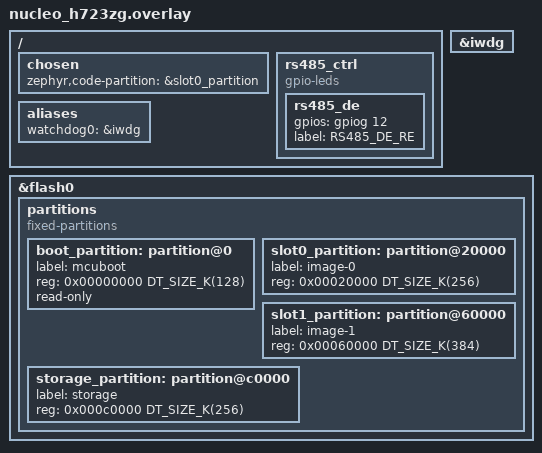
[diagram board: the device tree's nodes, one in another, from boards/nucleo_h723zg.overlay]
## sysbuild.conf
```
# Build MCUboot alongside the app (west build --sysbuild, implied by the
# presence of this file). Mode defaults to "swap using offset": MCUboot boots
# the new image on trial and automatically reverts to the previous one if it's
# never confirmed (see boot_write_img_confirmed() in src/main.c). No scratch
# partition is needed for this mode, matching the board's existing flash
# layout (same as fan_control_v2).
SB_CONFIG_BOOTLOADER_MCUBOOT=y
```

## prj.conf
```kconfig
# RS485 UART + DE GPIO
CONFIG_SERIAL=y
CONFIG_GPIO=y
CONFIG_UART_INTERRUPT_DRIVEN=y

# Hardware watchdog (IWDG): production safety net for the update flow. See
# APP_WDT_TIMEOUT_MS/APP_SELF_CONFIRM_GRACE_PERIOD_S in ./Kconfig.
# IWDG_STM32 auto-enables (default y, depends on the board's already-enabled
# &iwdg devicetree node).
CONFIG_WATCHDOG=y

# Settings-backed node address provisioning (rs485_envelope.c). Falls back to
# the board's existing storage_partition automatically - no devicetree change
# needed (settings_zms.c uses PARTITION_ID(storage_partition) when no
# zephyr,settings-partition chosen node exists).
#
# ZMS, not NVS: this board's erase-block-size is 128KB, but settings_nvs.c
# stores its sector size in a uint16_t (capped at 65535) and hard-errors
# with -EDOM ("Configuration error") the moment a hardware sector exceeds
# that - which every image on this board did, regardless of partition
# sizing. settings_zms.c's ZMS backend uses uint32_t instead and has no
# such ceiling; it's the intended replacement for exactly this case.
CONFIG_SETTINGS=y
CONFIG_ZMS=y
CONFIG_SETTINGS_ZMS=y

# Debug console on USART3 (ST-LINK VCP on this board, zephyr,console in the
# base devicetree) - a separate UART from LPUART1/RS485, safe to use for
# printk without disturbing the update transport.
CONFIG_CONSOLE=y
CONFIG_UART_CONSOLE=y
CONFIG_PRINTK=y
CONFIG_STDOUT_CONSOLE=y

# MCUboot image-manager, app side (same as fan_control_v2/prj.conf). IMG_MANAGER
# is needed for boot_write_img_confirmed(), and itself depends on FLASH_MAP +
# STREAM_FLASH (not auto-selected).
CONFIG_FLASH=y
CONFIG_FLASH_MAP=y
CONFIG_STREAM_FLASH=y
CONFIG_IMG_MANAGER=y
CONFIG_MCUBOOT_IMG_MANAGER=y

# mcumgr core + SMP-over-serial framing helpers. We deliberately do NOT enable
# CONFIG_MCUMGR_TRANSPORT_UART (it ties to a fixed zephyr,uart-mcumgr chosen
# console UART whose TX path can't be wrapped with RS485 DE control without
# patching a vendored Zephyr driver). Instead we drive the same shared
# encode/decode helpers (mcumgr_serial_tx_pkt/mcumgr_serial_process_frag) from
# our own transport in smp_rs485_transport.c.
CONFIG_NET_BUF=y
CONFIG_ZCBOR=y
CONFIG_BASE64=y
CONFIG_CRC=y
CONFIG_MCUMGR=y
# Selects CONFIG_MCUMGR_TRANSPORT_SERIAL_HAS_SMP_OVER_CONSOLE (see ./Kconfig) -
# that symbol has no prompt so it can't be set directly in a .conf fragment.
CONFIG_APP_RS485_SMP_TRANSPORT=y

# mcumgr command groups
CONFIG_MCUMGR_GRP_IMG=y
CONFIG_MCUMGR_GRP_OS=y

# Bumped so this build is a distinguishable, newer image for the mcumgr
# upload/test/confirm flow (adds the led1 1Hz blink) - not required for the
# swap itself (MCUBOOT_DOWNGRADE_PREVENTION isn't enabled), just for clarity.
CONFIG_MCUBOOT_IMGTOOL_SIGN_VERSION="0.0.1+0"

# Sizing
CONFIG_MCUMGR_TRANSPORT_NETBUF_SIZE=384
CONFIG_MCUMGR_TRANSPORT_NETBUF_COUNT=4
CONFIG_MAIN_STACK_SIZE=2048
CONFIG_SYSTEM_WORKQUEUE_STACK_SIZE=2304
```

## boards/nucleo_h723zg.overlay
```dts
/*
 * RS485 transceiver DE/RE control on PG12 (Arduino D7). RS485 data itself
 * rides LPUART1 (PB6/PB7 = Arduino D1/D0), already enabled by the board's
 * default devicetree - no pinctrl change needed here.
 */
/ {
	chosen {
		zephyr,code-partition = &slot0_partition;
	};

	rs485_ctrl: rs485_ctrl {
		compatible = "gpio-leds";

		rs485_de: rs485_de {
			gpios = <&gpiog 12 GPIO_ACTIVE_HIGH>;
			label = "RS485_DE_RE";
		};
	};

	aliases {
		watchdog0 = &iwdg;
	};
};

&iwdg {
	status = "okay";
};

/*
 * The upstream board devicetree doesn't define a flash partition table.
 * 1MB flash, 128KB erase sectors (stm32h723.dtsi) - every boundary below
 * lands on a sector boundary. No scratch partition: MCUboot's default
 * "swap using offset" mode doesn't need one (same as nucleo_g474re).
 *
 * storage gets 2 sectors (256K), not 1: settings_nvs.c's NVS backend
 * refuses to mount on fewer than 2 sectors (nvs_mount() in
 * subsys/kvss/nvs/nvs.c hard-errors "Configuration error - sector count"
 * below that) - it needs at least one spare sector to garbage-collect into.
 * A single 128K sector silently broke rs485_envelope_init() at boot (main()
 * returned before ever reaching the LED loop).
 *
 * slot1 (image-1) has ONE MORE sector than slot0 (image-0), not the same
 * count - required by swap-using-offset's app_max_size() (swap_offset.c):
 * it reserves a trailer sector in slot0 but a trailer *and* a padding sector
 * in slot1, so equal-sized slots make available_sec_sz compute to exactly
 * 0, capping the max bootable image size at 0 regardless of image content.
 * That's what actually caused "Image in the primary slot is not valid!"
 * for every image tried, verified via CONFIG_MCUBOOT_UTIL_LOG_LEVEL_DBG's
 * "TLV beyond image size" trace - not a signing or header problem at all.
 */
&flash0 {
	partitions {
		compatible = "fixed-partitions";
		#address-cells = <1>;
		#size-cells = <1>;

		boot_partition: partition@0 {
			label = "mcuboot";
			reg = <0x00000000 DT_SIZE_K(128)>;
			read-only;
		};

		slot0_partition: partition@20000 {
			label = "image-0";
			reg = <0x00020000 DT_SIZE_K(256)>;
		};

		slot1_partition: partition@60000 {
			label = "image-1";
			reg = <0x00060000 DT_SIZE_K(384)>;
		};

		storage_partition: partition@c0000 {
			label = "storage";
			reg = <0x000c0000 DT_SIZE_K(256)>;
		};
	};
};
```

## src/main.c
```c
#include <errno.h>
#include <zephyr/kernel.h>
#include <zephyr/device.h>
#include <zephyr/devicetree.h>
#include <zephyr/dfu/mcuboot.h>
#include <zephyr/drivers/gpio.h>
#include <zephyr/drivers/watchdog.h>
#include <zephyr/sys/printk.h>

#include "smp_rs485_transport.h"

#define LED0_NODE DT_ALIAS(led0)
#define LED1_NODE DT_ALIAS(led1)
#define WDT_NODE  DT_ALIAS(watchdog0)

/* LED1_TOGGLE_MS is a half-period (toggle interval), not a full cycle, so
 * 500ms here gives a 1Hz on/off blink rate - visual proof a new image (this
 * one) is actually running after an mcumgr update, distinct from led0's
 * faster 200ms heartbeat that both versions share.
 */
#define LED1_TOGGLE_MS 500

static const struct gpio_dt_spec led0 = GPIO_DT_SPEC_GET(LED0_NODE, gpios);
static const struct gpio_dt_spec led1 = GPIO_DT_SPEC_GET(LED1_NODE, gpios);
static const struct device *const wdt_dev = DEVICE_DT_GET(WDT_NODE);
static int wdt_channel_id = -1;

/*
 * Safety-net fallback: if the Pi never explicitly sends `mcumgr image
 * confirm` (mgmt/mcumgr/grp/img_mgmt/src/zephyr_img_mgmt.c's
 * img_mgmt_write_confirmed() already calls boot_write_img_confirmed() for
 * that path - no device code needed for it), the device confirms itself
 * after this many seconds of continuous, healthy operation, so it doesn't
 * stay in a perpetually-revertible "test" state for its whole operational
 * life. boot_is_img_confirmed() makes this a no-op if the Pi already
 * confirmed first.
 */
static void self_confirm_work_handler(struct k_work *work)
{
	ARG_UNUSED(work);

	if (!boot_is_img_confirmed()) {
		int rc = boot_write_img_confirmed();

		printk("rs485_mcumgr: self-confirm %s\n", rc == 0 ? "ok" : "failed");
	}
}
K_WORK_DELAYABLE_DEFINE(self_confirm_work, self_confirm_work_handler);

/*
 * Arms the IWDG so a bad update that hangs/crashes gets reset rather than
 * bricking the board: since the new image is never confirmed in that case,
 * MCUboot reverts to the last-known-good image on the next boot.
 * WDT_OPT_PAUSE_HALTED_BY_DBG freezes IWDG only while a debugger has the
 * core halted at a breakpoint - a no-op in production, but removes the
 * "resets while stepping" annoyance during development.
 */
static int watchdog_arm(void)
{
	if (!device_is_ready(wdt_dev)) {
		printk("rs485_mcumgr: watchdog not ready\n");
		return -ENODEV;
	}

	struct wdt_timeout_cfg wdt_cfg = {
		.window = {.min = 0, .max = CONFIG_APP_WDT_TIMEOUT_MS},
		.callback = NULL,
		.flags = WDT_FLAG_RESET_SOC,
	};

	wdt_channel_id = wdt_install_timeout(wdt_dev, &wdt_cfg);
	if (wdt_channel_id < 0) {
		printk("rs485_mcumgr: wdt_install_timeout failed: %d\n", wdt_channel_id);
		return wdt_channel_id;
	}

	return wdt_setup(wdt_dev, WDT_OPT_PAUSE_HALTED_BY_DBG);
}

int main(void)
{
	int ret;

	printk("rs485_mcumgr: starting (blinky v3, led1 1Hz)\n");

	ret = watchdog_arm();
	if (ret != 0) {
		printk("rs485_mcumgr: continuing without watchdog: %d\n", ret);
	}

	if (!gpio_is_ready_dt(&led0)) {
		printk("rs485_mcumgr: led0 not ready\n");
		return 0;
	}

	ret = gpio_pin_configure_dt(&led0, GPIO_OUTPUT_INACTIVE);
	if (ret != 0) {
		printk("rs485_mcumgr: led0 configure failed: %d\n", ret);
		return 0;
	}

	if (!gpio_is_ready_dt(&led1)) {
		printk("rs485_mcumgr: led1 not ready\n");
		return 0;
	}

	ret = gpio_pin_configure_dt(&led1, GPIO_OUTPUT_INACTIVE);
	if (ret != 0) {
		printk("rs485_mcumgr: led1 configure failed: %d\n", ret);
		return 0;
	}

	ret = smp_rs485_transport_init();
	if (ret != 0) {
		printk("rs485_mcumgr: transport init failed: %d\n", ret);
		return 0;
	}

	printk("rs485_mcumgr: ready, mcumgr reachable over RS485\n");

	/*
	 * Do NOT confirm immediately - give the Pi a chance to verify the new
	 * image is actually healthy and confirm it explicitly first. Schedule
	 * the grace-period fallback in case it never gets around to it.
	 */
	k_work_schedule(&self_confirm_work, K_SECONDS(CONFIG_APP_SELF_CONFIRM_GRACE_PERIOD_S));

	int elapsed_ms = 0;

	while (1) {
		gpio_pin_toggle_dt(&led0);
		if (wdt_channel_id >= 0) {
			wdt_feed(wdt_dev, wdt_channel_id);
		}

		elapsed_ms += 200;
		if (elapsed_ms >= LED1_TOGGLE_MS) {
			gpio_pin_toggle_dt(&led1);
			elapsed_ms -= LED1_TOGGLE_MS;
		}

		k_msleep(200);
	}

	return 0;
}
```

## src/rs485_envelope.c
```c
/*
 * Multi-drop RS485 addressing layer - see rs485_envelope.h.
 *
 * Frame layout on the wire:
 *
 *   offset  size  field    notes
 *   0       2     SOF      resync marker (RS485_SOF0/1), excluded from CRC
 *   2       1     DEST     destination address
 *   3       2     LEN      big-endian, length of PAYLOAD in bytes
 *   5       LEN   PAYLOAD  byte 0 = KIND, rest is KIND-specific body
 *   5+LEN   2     CRC16    big-endian, crc16_itu_t(0, DEST..end-of-PAYLOAD)
 *
 * On CRC failure (or an implausible LEN), the parser never trusts the
 * claimed length - it falls back to scanning byte-by-byte for the next SOF,
 * so a corrupted address/length byte can't misdeliver a frame or desync the
 * receiver for long.
 *
 * A node addressed by DEST buffers+validates the frame; everyone else just
 * counts down LEN+2 bytes and discards them with zero buffering, and never
 * transmits anything - required since RS485 is a shared broadcast medium
 * and two nodes replying at once is real bus contention.
 */

#include "rs485_envelope.h"
#include "rs485_uart.h"

#include <errno.h>
#include <stdbool.h>
#include <string.h>
#include <zephyr/kernel.h>
#include <zephyr/settings/settings.h>
#include <zephyr/sys/crc.h>

#define RS485_SOF0 0x9D
#define RS485_SOF1 0x3F

#define KIND_MCUMGR       0x00
#define KIND_PROVISIONING 0x01

#define PROV_SUBCMD_SET_ADDRESS     0x01
#define PROV_SUBCMD_SET_ADDRESS_ACK 0x02

/* Guards both the addressed-buffering and bystander-skip paths of the state
 * machine below - independent of, and in addition to, rs485_uart.c's own
 * line-accumulator inactivity timer, which guards a different layer's
 * partial state. Worst case ~535 bytes at 115200 baud is ~46ms, so 300ms of
 * envelope-level silence is unambiguously an abandoned/corrupted transfer.
 */
#define RS485_ENVELOPE_RX_TIMEOUT_MS 300

/* --- Address provisioning (Settings/NVS, backed by the board's existing
 * storage_partition - no devicetree change needed, settings_nvs.c already
 * falls back to that partition when no zephyr,settings-partition chosen
 * node exists). Sentinel 0xFF matches erased-NOR-flash convention. ---
 */
static uint8_t rs485_my_addr = RS485_ADDR_UNPROVISIONED;

static int rs485_addr_set(const char *name, size_t len, settings_read_cb read_cb, void *cb_arg)
{
	ARG_UNUSED(name);

	if (len != sizeof(rs485_my_addr)) {
		return -EINVAL;
	}

	ssize_t rc = read_cb(cb_arg, &rs485_my_addr, sizeof(rs485_my_addr));

	return rc < 0 ? (int)rc : 0;
}

SETTINGS_STATIC_HANDLER_DEFINE(rs485_addr, "rs485", NULL, rs485_addr_set, NULL, NULL);

/* --- Low-level framing: build+send one envelope frame. --- */

static void rs485_envelope_send_frame(uint8_t dest, uint8_t kind, const uint8_t *body,
				       uint16_t body_len)
{
	uint16_t payload_len = body_len + 1U; /* +1 for the KIND byte */
	uint8_t sof[2] = {RS485_SOF0, RS485_SOF1};
	uint8_t header[3];
	uint8_t crc_bytes[2];
	uint16_t crc;

	header[0] = dest;
	header[1] = (uint8_t)(payload_len >> 8);
	header[2] = (uint8_t)(payload_len & 0xFF);

	crc = crc16_itu_t(0, header, sizeof(header));
	crc = crc16_itu_t(crc, &kind, 1);
	crc = crc16_itu_t(crc, body, body_len);

	crc_bytes[0] = (uint8_t)(crc >> 8);
	crc_bytes[1] = (uint8_t)(crc & 0xFF);

	rs485_uart_de_assert();
	rs485_uart_raw_send(sof, sizeof(sof));
	rs485_uart_raw_send(header, sizeof(header));
	rs485_uart_raw_send(&kind, 1);
	rs485_uart_raw_send(body, body_len);
	rs485_uart_raw_send(crc_bytes, sizeof(crc_bytes));
	rs485_uart_de_deassert();
}

/* --- TX collect/flush (mcumgr path). --- */

static uint8_t tx_scratch[RS485_ENVELOPE_MAX_PAYLOAD - 1];
static size_t tx_scratch_len;

int rs485_envelope_tx_collect(const void *data, int len)
{
	if (len < 0 || tx_scratch_len + (size_t)len > sizeof(tx_scratch)) {
		return -ENOMEM;
	}

	memcpy(&tx_scratch[tx_scratch_len], data, (size_t)len);
	tx_scratch_len += (size_t)len;

	return 0;
}

int rs485_envelope_tx_flush(uint8_t dest_addr)
{
	rs485_envelope_send_frame(dest_addr, KIND_MCUMGR, tx_scratch, (uint16_t)tx_scratch_len);
	tx_scratch_len = 0;

	return 0;
}

/* --- Provisioning: deferred to a workqueue since it writes flash
 * (settings_save_one() is not ISR-safe), unlike the mcumgr fast path which
 * only ever copies bytes in ISR context.
 * ---
 */

static uint8_t prov_pending_addr;

static void prov_work_handler(struct k_work *work)
{
	ARG_UNUSED(work);

	uint8_t new_addr = prov_pending_addr;

	if (new_addr < RS485_ADDR_NODE_MIN || new_addr > RS485_ADDR_NODE_MAX) {
		return;
	}

	if (settings_save_one("rs485/addr", &new_addr, sizeof(new_addr)) != 0) {
		return;
	}

	rs485_my_addr = new_addr;

	uint8_t ack_body[2] = {PROV_SUBCMD_SET_ADDRESS_ACK, new_addr};

	rs485_envelope_send_frame(RS485_ADDR_HOST, KIND_PROVISIONING, ack_body,
				   sizeof(ack_body));
}

K_WORK_DEFINE(prov_work, prov_work_handler);

/* --- RX state machine. --- */

enum rx_state {
	RX_WAIT_SOF1,
	RX_WAIT_SOF2,
	RX_WAIT_DEST,
	RX_WAIT_LEN_HI,
	RX_WAIT_LEN_LO,
	RX_PAYLOAD,
	RX_WAIT_CRC_HI,
	RX_WAIT_CRC_LO,
};

static enum rx_state rx_state = RX_WAIT_SOF1;
static uint8_t rx_dest;
static uint16_t rx_len;
static uint16_t rx_count;
static bool rx_buffering;
static uint8_t rx_buf[RS485_ENVELOPE_MAX_PAYLOAD];
static uint8_t rx_crc_hi;

static void rx_reset(void)
{
	rx_state = RX_WAIT_SOF1;
	rx_len = 0;
	rx_count = 0;
	rx_buffering = false;
}

static void rx_timeout_expired(struct k_timer *timer)
{
	ARG_UNUSED(timer);

	unsigned int key = irq_lock();

	rx_reset();

	irq_unlock(key);
}

K_TIMER_DEFINE(rs485_envelope_rx_timer, rx_timeout_expired, NULL);

/* Handles one fully-received, CRC-validated frame addressed to this node.
 * Called with the state machine's irq_lock held (see rs485_envelope_rx_byte()) -
 * the mcumgr replay loop below is bounded (<= RS485_ENVELOPE_MAX_PAYLOAD
 * iterations of simple work), so holding interrupts disabled for it is
 * negligible at 115200 baud and eliminates any race with a new frame
 * starting to overwrite rx_buf before this one is fully replayed.
 */
static void dispatch_frame(uint8_t *buf, uint16_t len)
{
	uint8_t kind = buf[0];
	uint16_t body_len = len - 1U;

	if (kind == KIND_MCUMGR) {
		for (uint16_t i = 0; i < body_len; i++) {
			rs485_uart_feed_payload_byte(buf[1 + i]);
		}
	} else if (kind == KIND_PROVISIONING && body_len == 2 &&
		   buf[1] == PROV_SUBCMD_SET_ADDRESS) {
		prov_pending_addr = buf[2];
		k_work_submit(&prov_work);
	}
}

void rs485_envelope_rx_byte(uint8_t byte)
{
	unsigned int key;

	k_timer_start(&rs485_envelope_rx_timer, K_MSEC(RS485_ENVELOPE_RX_TIMEOUT_MS), K_NO_WAIT);

	key = irq_lock();

	switch (rx_state) {
	case RX_WAIT_SOF1:
		if (byte == RS485_SOF0) {
			rx_state = RX_WAIT_SOF2;
		}
		break;

	case RX_WAIT_SOF2:
		if (byte == RS485_SOF1) {
			rx_state = RX_WAIT_DEST;
		} else if (byte != RS485_SOF0) {
			rx_state = RX_WAIT_SOF1;
		}
		/* else: byte == RS485_SOF0 again - stay here, handles
		 * overlapping marker bytes.
		 */
		break;

	case RX_WAIT_DEST:
		rx_dest = byte;
		rx_state = RX_WAIT_LEN_HI;
		break;

	case RX_WAIT_LEN_HI:
		rx_len = (uint16_t)byte << 8;
		rx_state = RX_WAIT_LEN_LO;
		break;

	case RX_WAIT_LEN_LO:
		rx_len |= byte;
		rx_count = 0;
		if (rx_len == 0 || rx_len > sizeof(rx_buf)) {
			/* Implausible - resync instead of trusting it. */
			rx_reset();
			break;
		}
		rx_buffering = (rx_dest == rs485_my_addr) || (rx_dest == RS485_ADDR_BROADCAST);
		rx_state = RX_PAYLOAD;
		break;

	case RX_PAYLOAD:
		if (rx_buffering) {
			rx_buf[rx_count] = byte;
		}
		rx_count++;
		if (rx_count >= rx_len) {
			rx_state = RX_WAIT_CRC_HI;
		}
		break;

	case RX_WAIT_CRC_HI:
		rx_crc_hi = byte;
		rx_state = RX_WAIT_CRC_LO;
		break;

	case RX_WAIT_CRC_LO:
		if (rx_buffering) {
			uint16_t got_crc = ((uint16_t)rx_crc_hi << 8) | byte;
			uint8_t header[3];
			uint16_t want_crc;

			header[0] = rx_dest;
			header[1] = (uint8_t)(rx_len >> 8);
			header[2] = (uint8_t)(rx_len & 0xFF);
			want_crc = crc16_itu_t(0, header, sizeof(header));
			want_crc = crc16_itu_t(want_crc, rx_buf, rx_len);

			if (got_crc == want_crc) {
				dispatch_frame(rx_buf, rx_len);
			}
			/* CRC mismatch: silently drop, resync below. */
		}
		rx_reset();
		break;
	}

	irq_unlock(key);
}

int rs485_envelope_init(void)
{
	int rc;

	rc = settings_subsys_init();
	if (rc != 0) {
		return rc;
	}

	rc = settings_load();
	if (rc != 0) {
		return rc;
	}

	return rs485_uart_init();
}
```

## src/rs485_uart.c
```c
#include "rs485_uart.h"
#include "rs485_envelope.h"

#include <errno.h>
#include <zephyr/device.h>
#include <zephyr/devicetree.h>
#include <zephyr/drivers/gpio.h>
#include <zephyr/drivers/uart.h>
#include <zephyr/kernel.h>

#define UART_NODE     DT_NODELABEL(lpuart1)
#define RS485_DE_NODE DT_NODELABEL(rs485_de)

#if !DT_NODE_HAS_STATUS(UART_NODE, okay)
#error "lpuart1 is not enabled in devicetree"
#endif

#if !DT_NODE_HAS_STATUS(RS485_DE_NODE, okay)
#error "rs485_de node is not enabled in devicetree"
#endif

static const struct device *const uart_dev = DEVICE_DT_GET(UART_NODE);
static const struct gpio_dt_spec rs485_de = GPIO_DT_SPEC_GET(RS485_DE_NODE, gpios);

/* Fragments (complete lines) waiting to be decoded off the ISR's hands. */
K_MEM_SLAB_DEFINE(rs485_rx_slab, sizeof(struct rs485_rx_buf), RS485_RX_BUF_COUNT, 1);

static rs485_rx_frag_fn *rs485_rx_cb;
static rs485_rx_idle_fn *rs485_rx_idle_cb;
static struct rs485_rx_buf *rs485_cur_rx_buf;
static bool rs485_rx_ignoring;

/* A noise burst or aborted transfer with no trailing '\n' would otherwise
 * leave a partial line sitting forever, corrupting whatever legitimate bytes
 * arrive next. Restarted on every received byte; on expiry, discards any
 * in-progress line and lets a higher layer (the SMP transport) discard its
 * own in-progress multi-line reassembly state too via rs485_rx_idle_cb.
 */
#define RS485_RX_INACTIVITY_TIMEOUT_MS 300

static void rs485_rx_timeout_expired(struct k_timer *timer)
{
	ARG_UNUSED(timer);

	unsigned int key = irq_lock();

	if (rs485_cur_rx_buf != NULL) {
		rs485_uart_free_rx_buf(rs485_cur_rx_buf);
		rs485_cur_rx_buf = NULL;
	}
	rs485_rx_ignoring = false;

	irq_unlock(key);

	if (rs485_rx_idle_cb != NULL) {
		rs485_rx_idle_cb();
	}
}

K_TIMER_DEFINE(rs485_rx_timeout_timer, rs485_rx_timeout_expired, NULL);

static struct rs485_rx_buf *rs485_alloc_rx_buf(void)
{
	struct rs485_rx_buf *rx_buf;
	void *block;

	if (k_mem_slab_alloc(&rs485_rx_slab, &block, K_NO_WAIT) != 0) {
		return NULL;
	}

	rx_buf = block;
	rx_buf->length = 0;
	return rx_buf;
}

void rs485_uart_free_rx_buf(struct rs485_rx_buf *rx_buf)
{
	k_mem_slab_free(&rs485_rx_slab, rx_buf);
}

void rs485_uart_register_rx_cb(rs485_rx_frag_fn *cb)
{
	rs485_rx_cb = cb;
}

void rs485_uart_register_rx_idle_cb(rs485_rx_idle_fn *cb)
{
	rs485_rx_idle_cb = cb;
}

/* Accumulates one incoming (already envelope-unwrapped) payload byte;
 * dispatches to the registered rx callback once a line (terminated by '\n')
 * has been received, mirroring uart_mcumgr_rx_byte().
 *
 * rs485_cur_rx_buf/rs485_rx_ignoring are shared with the RX inactivity timer
 * (rs485_rx_timeout_expired(), a separate interrupt context) and so are
 * protected by irq_lock() here, not just implicitly single-threaded as when
 * only the UART ISR touched them.
 */
void rs485_uart_feed_payload_byte(uint8_t byte)
{
	struct rs485_rx_buf *rx_buf;
	struct rs485_rx_buf *completed = NULL;
	unsigned int key;

	/* Restart the "no byte for N ms" clock on every byte - k_timer_start()
	 * internally re-arms from now even if already running.
	 */
	k_timer_start(&rs485_rx_timeout_timer, K_MSEC(RS485_RX_INACTIVITY_TIMEOUT_MS), K_NO_WAIT);

	key = irq_lock();

	if (!rs485_rx_ignoring) {
		if (rs485_cur_rx_buf == NULL) {
			rs485_cur_rx_buf = rs485_alloc_rx_buf();
			if (rs485_cur_rx_buf == NULL) {
				rs485_rx_ignoring = true;
			}
		}
	}

	rx_buf = rs485_cur_rx_buf;
	if (!rs485_rx_ignoring) {
		if (rx_buf->length >= sizeof(rx_buf->data)) {
			rs485_uart_free_rx_buf(rs485_cur_rx_buf);
			rs485_cur_rx_buf = NULL;
			rs485_rx_ignoring = true;
		} else {
			rx_buf->data[rx_buf->length++] = byte;
		}
	}

	if (byte == '\n') {
		if (rs485_rx_ignoring) {
			rs485_rx_ignoring = false;
		} else {
			rs485_cur_rx_buf = NULL;
			completed = rx_buf;
		}
	}

	irq_unlock(key);

	if (completed != NULL && rs485_rx_cb != NULL) {
		rs485_rx_cb(completed);
	}
}

static void rs485_uart_isr(const struct device *dev, void *user_data)
{
	uint8_t buf[32];
	int chunk_len;

	ARG_UNUSED(user_data);

	while (uart_irq_update(dev) && uart_irq_is_pending(dev)) {
		if (!uart_irq_rx_ready(dev)) {
			continue;
		}

		chunk_len = uart_fifo_read(dev, buf, sizeof(buf));
		for (int i = 0; i < chunk_len; i++) {
			rs485_envelope_rx_byte(buf[i]);
		}
	}
}

void rs485_uart_de_assert(void)
{
	gpio_pin_set_dt(&rs485_de, 1);
	k_busy_wait(100);
}

void rs485_uart_de_deassert(void)
{
	/* uart_poll_out() only guarantees the shift register was free for the
	 * PREVIOUS byte, not that the LAST byte finished shifting out onto the
	 * wire - wait comfortably longer than one frame time (10 bits @ 115200
	 * baud = ~87us) before dropping DE, exactly as validated in the rs485
	 * test project.
	 */
	k_busy_wait(200);
	k_busy_wait(20);
	gpio_pin_set_dt(&rs485_de, 0);
}

int rs485_uart_raw_send(const void *data, int len)
{
	const uint8_t *p = data;

	while (len--) {
		uart_poll_out(uart_dev, *p++);
	}

	return 0;
}

int rs485_uart_init(void)
{
	if (!device_is_ready(uart_dev)) {
		return -ENODEV;
	}

	if (!gpio_is_ready_dt(&rs485_de)) {
		return -ENODEV;
	}

	int ret = gpio_pin_configure_dt(&rs485_de, GPIO_OUTPUT_INACTIVE);

	if (ret != 0) {
		return ret;
	}

	uart_irq_rx_disable(uart_dev);
	uart_irq_tx_disable(uart_dev);
	uart_irq_callback_set(uart_dev, rs485_uart_isr);
	uart_irq_rx_enable(uart_dev);

	return 0;
}
```

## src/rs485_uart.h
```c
#ifndef RS485_UART_H_
#define RS485_UART_H_

#include <stdint.h>
#include <zephyr/types.h>

/* Must satisfy RS485_RX_BUF_COUNT * RS485_RX_BUF_SIZE >= CONFIG_MCUMGR_TRANSPORT_NETBUF_SIZE,
 * mirroring the relation Zephyr's own uart_mcumgr driver documents for
 * CONFIG_UART_MCUMGR_RX_BUF_COUNT/CONFIG_UART_MCUMGR_RX_BUF_SIZE.
 */
#define RS485_RX_BUF_SIZE  128
#define RS485_RX_BUF_COUNT 4

/** A single received mcumgr-over-serial fragment (one line, up to and including '\n'). */
struct rs485_rx_buf {
	void *fifo_reserved; /* 1st word reserved for use by k_fifo */
	uint8_t data[RS485_RX_BUF_SIZE];
	int length;
};

/** Called from ISR context when a complete line has been received. */
typedef void rs485_rx_frag_fn(struct rs485_rx_buf *rx_buf);

/**
 * Called (from timer-ISR context) when no byte has arrived for
 * RS485_RX_INACTIVITY_TIMEOUT_MS - lets a higher layer (the SMP transport)
 * discard any of its own in-progress multi-line reassembly state, since the
 * line-level buffer that fed it has just been discarded too.
 */
typedef void rs485_rx_idle_fn(void);

/**
 * Brings up the LPUART1 device (already pinned to PB6/PB7 = Arduino D1/D0 by
 * the board's default devicetree) and the RS485 DE/RE GPIO (PG12 = Arduino D7),
 * and starts interrupt-driven RX byte capture. Must be called before any
 * other rs485_uart_* function.
 */
int rs485_uart_init(void);

/** Registers the callback invoked (from ISR context) for each completed line. */
void rs485_uart_register_rx_cb(rs485_rx_frag_fn *cb);

/**
 * Feeds one payload byte (already unwrapped/validated by the addressing
 * envelope layer, rs485_envelope.c) into the line accumulator. Invokes the
 * registered rx callback itself once a complete line ('\n'-terminated) has
 * been accumulated. Runs in ISR context (called from the envelope layer's
 * own ISR-context byte handler).
 */
void rs485_uart_feed_payload_byte(uint8_t byte);

/**
 * Registers the callback invoked (from timer-ISR context) when the RX
 * inactivity timeout fires, i.e. a partial/aborted line was just discarded.
 */
void rs485_uart_register_rx_idle_cb(rs485_rx_idle_fn *cb);

/** Returns a completed rx buffer to the pool once its contents have been processed. */
void rs485_uart_free_rx_buf(struct rs485_rx_buf *rx_buf);

/**
 * Raises DE (transmit mode) and waits for the transceiver to settle. Must be
 * paired with a subsequent rs485_uart_de_deassert() call.
 */
void rs485_uart_de_assert(void);

/**
 * Waits for the last transmitted byte to finish shifting out, then drops DE
 * (receive mode).
 */
void rs485_uart_de_deassert(void);

/**
 * Dumb byte pusher with no DE handling of its own - matches the
 * mcumgr_serial_tx_cb signature exactly so it can be passed directly to
 * mcumgr_serial_tx_pkt(). Callers must wrap it with
 * rs485_uart_de_assert()/rs485_uart_de_deassert().
 */
int rs485_uart_raw_send(const void *data, int len);

#endif /* RS485_UART_H_ */
```
